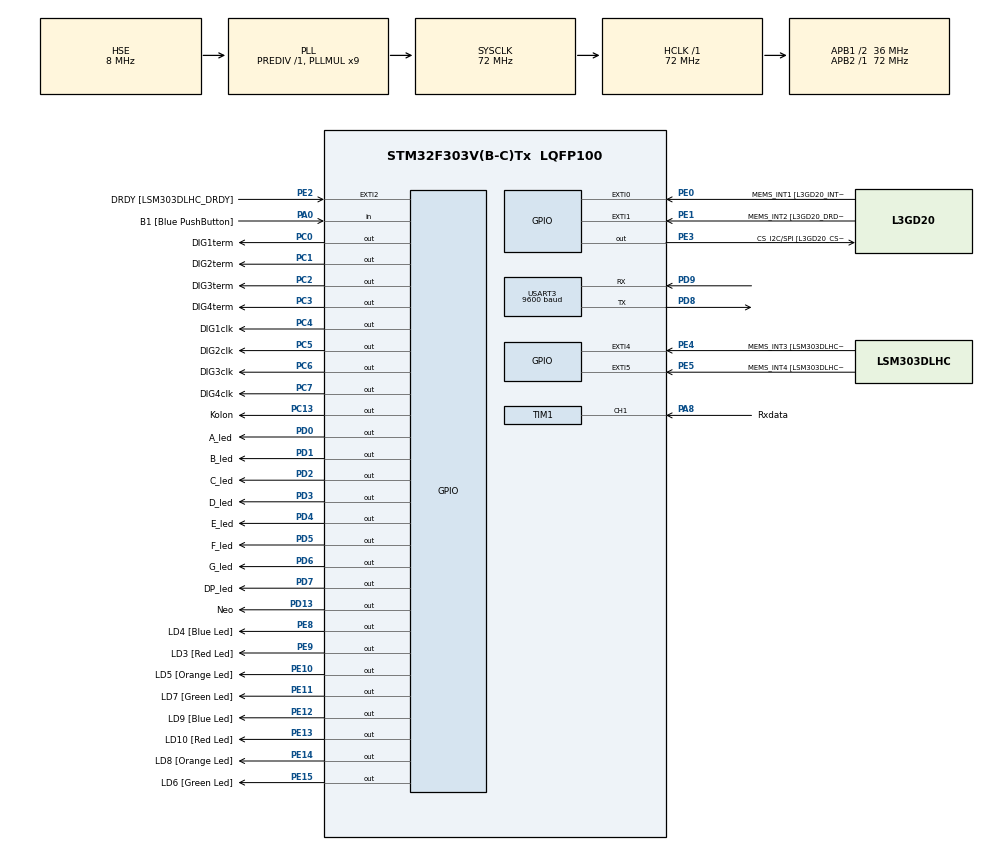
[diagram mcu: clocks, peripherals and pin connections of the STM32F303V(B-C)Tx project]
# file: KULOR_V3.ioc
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CRC.CRCLength=CRC_POLYLENGTH_8B
CRC.DefaultInitValueUse=DEFAULT_INIT_VALUE_DISABLE
CRC.DefaultPolynomialUse=DEFAULT_POLYNOMIAL_DISABLE
CRC.GeneratingPolynomial=X5+X4+X0
CRC.InputDataFormat=CRC_INPUTDATA_FORMAT_WORDS
FREERTOS.Tasks01=defaultTask,0,128,StartDefaultTask,Default,NULL
Mcu.Family=STM32F3
Mcu.Name=STM32F303V(B-C)Tx
Mcu.Package=LQFP100
NVIC.PriorityGroup=NVIC_PRIORITYGROUP_4
NVIC.TIM1_CC_IRQn=true\:5\:0\:false\:false\:true\:true
NVIC.TIM2_IRQn=true\:0\:0\:false\:false\:true\:false
NVIC.TimeBase=TIM2_IRQn
NVIC.TimeBaseIP=TIM2
PA0.GPIO_Label=B1 [Blue PushButton]
PA0.GPIO_Mode=GPIO_MODE_INPUT
PA0.GPIO_PuPd=GPIO_NOPULL
PA0.Signal=GPIO_Input
PA11.GPIO_Label=DM
PA11.Signal=USB_DM
PA12.GPIO_Label=DP
PA12.Signal=USB_DP
PA13.GPIO_Label=SWDIO
PA13.Signal=SYS_JTMS-SWDIO
PA14.GPIO_Label=SWCLK
PA14.Signal=SYS_JTCK-SWCLK
PA5.GPIO_Label=SPI1_SCK [L3GD20_SCL/SPC]
PA5.GPIO_Mode=GPIO_MODE_AF_PP
PA5.GPIO_PuPd=GPIO_NOPULL
PA5.GPIO_Speed=GPIO_SPEED_FREQ_LOW
PA5.Signal=SPI1_SCK
PA6.GPIO_Label=SPI1_MISO [L3GD20_SA0/SDO]
PA6.GPIO_Mode=GPIO_MODE_AF_PP
PA6.GPIO_PuPd=GPIO_NOPULL
PA6.GPIO_Speed=GPIO_SPEED_FREQ_LOW
PA6.Signal=SPI1_MISO
PA7.GPIO_Label=SPI1_MISO [L3GD20_SDA/SDI/SDO]
PA7.GPIO_Mode=GPIO_MODE_AF_PP
PA7.GPIO_PuPd=GPIO_NOPULL
PA7.GPIO_Speed=GPIO_SPEED_FREQ_LOW
PA7.Signal=SPI1_MOSI
PA8.GPIO_Label=Rxdata
PA8.Signal=S_TIM1_CH1
PB3.GPIO_Label=SWO
PB3.Signal=SYS_JTDO-TRACESWO
PB6.GPIO_FM6=__NULL
PB6.GPIO_Label=I2C1_SCL [LSM303DLHC_SCL]
PB6.GPIO_Mode=GPIO_MODE_AF_OD
PB6.GPIO_PuPd=GPIO_NOPULL
PB6.GPIO_Speed=GPIO_SPEED_FREQ_LOW
PB6.Signal=I2C1_SCL
PB7.GPIO_FM7=__NULL
PB7.GPIO_Label=I2C1_SDA [LSM303DLHC_SDA]
PB7.GPIO_Mode=GPIO_MODE_AF_OD
PB7.GPIO_PuPd=GPIO_NOPULL
PB7.GPIO_Speed=GPIO_SPEED_FREQ_LOW
PB7.Signal=I2C1_SDA
PC0.GPIO_Label=DIG1term
PC0.Signal=GPIO_Output
PC1.GPIO_Label=DIG2term
PC1.Signal=GPIO_Output
PC13.GPIO_Label=Kolon
PC13.Signal=GPIO_Output
PC14-OSC32_IN.GPIO_Label=OSC32_IN
PC14-OSC32_IN.Signal=RCC_OSC32_IN
PC15-OSC32_OUT.GPIO_Label=OSC32_OUT
PC15-OSC32_OUT.Signal=RCC_OSC32_OUT
PC2.GPIO_Label=DIG3term
PC2.Signal=GPIO_Output
PC3.GPIO_Label=DIG4term
PC3.Signal=GPIO_Output
PC4.GPIO_Label=DIG1clk
PC4.Signal=GPIO_Output
PC5.GPIO_Label=DIG2clk
PC5.Signal=GPIO_Output
PC6.GPIO_Label=DIG3clk
PC6.Signal=GPIO_Output
PC7.GPIO_Label=DIG4clk
PC7.Signal=GPIO_Output
PD0.GPIO_Label=A_led
PD0.Signal=GPIO_Output
PD1.GPIO_Label=B_led
PD1.Signal=GPIO_Output
PD13.GPIO_Label=Neo
PD13.Signal=GPIO_Output
PD2.GPIO_Label=C_led
PD2.Signal=GPIO_Output
PD3.GPIO_Label=D_led
PD3.Signal=GPIO_Output
PD4.GPIO_Label=E_led
PD4.Signal=GPIO_Output
PD5.GPIO_Label=F_led
PD5.Signal=GPIO_Output
PD6.GPIO_Label=G_led
PD6.Signal=GPIO_Output
PD7.GPIO_Label=DP_led
PD7.Signal=GPIO_Output
PD8.Mode=Asynchronous
PD8.Signal=USART3_TX
PD9.Mode=Asynchronous
PD9.Signal=USART3_RX
PE0.GPIO_Label=MEMS_INT1 [L3GD20_INT1]
PE0.GPIO_ModeDefaultEXTI=GPIO_MODE_EVT_RISING
PE0.GPIO_PuPd=GPIO_NOPULL
PE0.Signal=GPXTI0
PE1.GPIO_Label=MEMS_INT2 [L3GD20_DRDY/INT2]
PE1.GPIO_ModeDefaultEXTI=GPIO_MODE_EVT_RISING
PE1.GPIO_PuPd=GPIO_NOPULL
PE1.Signal=GPXTI1
PE10.GPIO_Label=LD5 [Orange Led]
PE10.GPIO_ModeDefaultOutputPP=GPIO_MODE_OUTPUT_PP
PE10.GPIO_PuPd=GPIO_NOPULL
PE10.GPIO_Speed=GPIO_SPEED_FREQ_LOW
PE10.Signal=GPIO_Output
PE11.GPIO_Label=LD7 [Green Led]
PE11.GPIO_ModeDefaultOutputPP=GPIO_MODE_OUTPUT_PP
PE11.GPIO_PuPd=GPIO_NOPULL
PE11.GPIO_Speed=GPIO_SPEED_FREQ_LOW
PE11.Signal=GPIO_Output
PE12.GPIO_Label=LD9 [Blue Led]
PE12.GPIO_ModeDefaultOutputPP=GPIO_MODE_OUTPUT_PP
PE12.GPIO_PuPd=GPIO_NOPULL
PE12.GPIO_Speed=GPIO_SPEED_FREQ_LOW
PE12.Signal=GPIO_Output
PE13.GPIO_Label=LD10 [Red Led]
PE13.GPIO_ModeDefaultOutputPP=GPIO_MODE_OUTPUT_PP
PE13.GPIO_PuPd=GPIO_NOPULL
PE13.GPIO_Speed=GPIO_SPEED_FREQ_LOW
PE13.Signal=GPIO_Output
PE14.GPIO_Label=LD8 [Orange Led]
PE14.GPIO_ModeDefaultOutputPP=GPIO_MODE_OUTPUT_PP
PE14.GPIO_PuPd=GPIO_NOPULL
PE14.GPIO_Speed=GPIO_SPEED_FREQ_LOW
PE14.Signal=GPIO_Output
PE15.GPIO_Label=LD6 [Green Led]
PE15.GPIO_ModeDefaultOutputPP=GPIO_MODE_OUTPUT_PP
PE15.GPIO_PuPd=GPIO_NOPULL
PE15.GPIO_Speed=GPIO_SPEED_FREQ_LOW
PE15.Signal=GPIO_Output
PE2.GPIO_Label=DRDY [LSM303DLHC_DRDY]
PE2.GPIO_ModeDefaultEXTI=GPIO_MODE_EVT_RISING
PE2.GPIO_PuPd=GPIO_NOPULL
PE2.Signal=GPXTI2
PE3.GPIO_Label=CS_I2C/SPI [L3GD20_CS_I2C/SPI]
PE3.GPIO_ModeDefaultOutputPP=GPIO_MODE_OUTPUT_PP
PE3.GPIO_PuPd=GPIO_NOPULL
PE3.GPIO_Speed=GPIO_SPEED_FREQ_LOW
PE3.Signal=GPIO_Output
PE4.GPIO_Label=MEMS_INT3 [LSM303DLHC_INT1]
PE4.GPIO_ModeDefaultEXTI=GPIO_MODE_EVT_RISING
PE4.GPIO_PuPd=GPIO_NOPULL
PE4.Signal=GPXTI4
PE5.GPIO_Label=MEMS_INT4 [LSM303DLHC_INT2]
PE5.GPIO_ModeDefaultEXTI=GPIO_MODE_EVT_RISING
PE5.GPIO_PuPd=GPIO_NOPULL
PE5.Signal=GPXTI5
PE8.GPIO_Label=LD4 [Blue Led]
PE8.GPIO_ModeDefaultOutputPP=GPIO_MODE_OUTPUT_PP
PE8.GPIO_PuPd=GPIO_NOPULL
PE8.GPIO_Speed=GPIO_SPEED_FREQ_LOW
PE8.Signal=GPIO_Output
PE9.GPIO_Label=LD3 [Red Led]
PE9.GPIO_ModeDefaultOutputPP=GPIO_MODE_OUTPUT_PP
PE9.GPIO_PuPd=GPIO_NOPULL
PE9.GPIO_Speed=GPIO_SPEED_FREQ_LOW
PE9.Signal=GPIO_Output
PF0-OSC_IN.GPIO_Label=OSC_IN
PF0-OSC_IN.Mode=HSE-External-Oscillator
PF0-OSC_IN.Signal=RCC_OSC_IN
PF1-OSC_OUT.GPIO_Label=OSC_OUT
PF1-OSC_OUT.Mode=HSE-External-Oscillator
PF1-OSC_OUT.Signal=RCC_OSC_OUT
ProjectManager.HeapSize=0x200
ProjectManager.StackSize=0x400
ProjectManager.TargetToolchain=EWARM
RCC.AHBFreq_Value=72000000
RCC.APB1CLKDivider=RCC_HCLK_DIV2
RCC.APB1Freq_Value=36000000
RCC.APB1TimFreq_Value=72000000
RCC.APB2Freq_Value=72000000
RCC.APB2TimFreq_Value=72000000
RCC.CortexFreq_Value=72000000
RCC.HCLKFreq_Value=72000000
RCC.HSE_VALUE=8000000
RCC.HSIState=RCC_HSI_ON
RCC.HSI_VALUE=8000000
RCC.LSE_VALUE=32768
RCC.PLLMUL=RCC_PLL_MUL9
RCC.PLLSourceVirtual=RCC_PLLSOURCE_HSE
RCC.SYSCLKFreq_VALUE=72000000
RCC.SYSCLKSourceVirtual=RCC_SYSCLKSOURCE_PLLCLK
RCC.USBFreq_Value=72000000
SH.S_TIM1_CH1.0=TIM1_CH1,TriggerSource_TI1FP1
SH.S_TIM1_CH1.1=TIM1_CH1,Input_Capture1_from_TI1
SH.S_TIM1_CH1.2=TIM1_CH1,Input_Capture2_from_TI1
TIM1.Channel-Input_Capture2_from_TI1=TIM_CHANNEL_2
TIM1.ICPolarity_CH2=TIM_INPUTCHANNELPOLARITY_FALLING
TIM1.Period=0xFFFF
TIM1.Prescaler=71
USART3.BaudRate=9600
VP_CRC_VS_CRC.Mode=CRC_Activate
VP_FREERTOS_VS_ENABLE.Mode=Enabled
VP_RTC_VS_RTC_Activate.Mode=RTC_Enabled
VP_RTC_VS_RTC_Calendar.Mode=RTC_Calendar
VP_SYS_VS_tim2.Mode=TIM2
VP_TIM1_VS_ClockSourceINT.Mode=Internal
VP_TIM1_VS_ControllerModeReset.Mode=Reset Mode
board=STM32F3DISCOVERY

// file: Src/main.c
/**
  ******************************************************************************
  * File Name          : main.c
  * Description        : Main program body
  ******************************************************************************
  *
  * Copyright (c) 2017 STMicroelectronics International N.V.
  * All rights reserved.
  *
  * Redistribution and use in source and binary forms, with or without
  * modification, are permitted, provided that the following conditions are met:

  ******************************************************************************
  */
#include "main.h"
#include "stm32f3xx_hal.h"
#include "cmsis_os.h"
#include "crc.h"
#include "rtc.h"
#include "tim.h"
#include "usart.h"
#include "gpio.h"
#include "stm32f3_discovery.h"
#include "Kulor_Funktioner.h"

/* USER CODE BEGIN PV */
/* Private variables ---------------------------------------------------------*/

/* USER CODE END PV */

void SystemClock_Config(void);
void Error_Handler(void);
void MX_FREERTOS_Init(void);

/* USER CODE BEGIN PFP */
/* Private function prototypes -----------------------------------------------*/

/* USER CODE END PFP */

int main(void)
{

  /* MCU Configuration----------------------------------------------------------*/

  /* Reset of all peripherals, Initializes the Flash interface and the Systick. */
  HAL_Init();

  /* Configure the system clock */
  SystemClock_Config();

  /* Initialize all configured peripherals */
  MX_GPIO_Init();
  MX_CRC_Init();
  MX_RTC_Init();
  MX_TIM1_Init();
  MX_USART3_UART_Init();
  RTC_CLOCK_SETINGS();
  /* USER CODE BEGIN 2 */
   set_clock_serial();
  /* USER CODE END 2 */

  /* Call init function for freertos objects (in freertos.c) */
  MX_FREERTOS_Init();

  /* Start scheduler */
  osKernelStart();

  /* We should never get here as control is now taken by the scheduler */

  /* Infinite loop */
  while (1)
  {

  }

}

/** System Clock Configuration
*/
void SystemClock_Config(void)
{

  RCC_OscInitTypeDef RCC_OscInitStruct;
  RCC_ClkInitTypeDef RCC_ClkInitStruct;
  RCC_PeriphCLKInitTypeDef PeriphClkInit;

    /**Initializes the CPU, AHB and APB busses clocks
    */
  RCC_OscInitStruct.OscillatorType = RCC_OSCILLATORTYPE_LSI|RCC_OSCILLATORTYPE_HSE;
  RCC_OscInitStruct.HSEState = RCC_HSE_ON;
  RCC_OscInitStruct.HSEPredivValue = RCC_HSE_PREDIV_DIV1;
  RCC_OscInitStruct.HSIState = RCC_HSI_ON;
  RCC_OscInitStruct.LSIState = RCC_LSI_ON;
  RCC_OscInitStruct.PLL.PLLState = RCC_PLL_ON;
  RCC_OscInitStruct.PLL.PLLSource = RCC_PLLSOURCE_HSE;
  RCC_OscInitStruct.PLL.PLLMUL = RCC_PLL_MUL9;
  if (HAL_RCC_OscConfig(&RCC_OscInitStruct) != HAL_OK)
  {
    Error_Handler();
  }

    /**Initializes the CPU, AHB and APB busses clocks
    */
  RCC_ClkInitStruct.ClockType = RCC_CLOCKTYPE_HCLK|RCC_CLOCKTYPE_SYSCLK
                              |RCC_CLOCKTYPE_PCLK1|RCC_CLOCKTYPE_PCLK2;
  RCC_ClkInitStruct.SYSCLKSource = RCC_SYSCLKSOURCE_PLLCLK;
  RCC_ClkInitStruct.AHBCLKDivider = RCC_SYSCLK_DIV1;
  RCC_ClkInitStruct.APB1CLKDivider = RCC_HCLK_DIV2;
  RCC_ClkInitStruct.APB2CLKDivider = RCC_HCLK_DIV1;

  if (HAL_RCC_ClockConfig(&RCC_ClkInitStruct, FLASH_LATENCY_2) != HAL_OK)
  {
    Error_Handler();
  }

  PeriphClkInit.PeriphClockSelection = RCC_PERIPHCLK_USART3|RCC_PERIPHCLK_RTC
                              |RCC_PERIPHCLK_TIM1;
  PeriphClkInit.Usart3ClockSelection = RCC_USART3CLKSOURCE_PCLK1;
  PeriphClkInit.RTCClockSelection = RCC_RTCCLKSOURCE_LSI;
  PeriphClkInit.Tim1ClockSelection = RCC_TIM1CLK_HCLK;
  if (HAL_RCCEx_PeriphCLKConfig(&PeriphClkInit) != HAL_OK)
  {
    Error_Handler();
  }

    /**Configure the Systick interrupt time
    */
  HAL_SYSTICK_Config(HAL_RCC_GetHCLKFreq()/1000);

    /**Configure the Systick
    */
  HAL_SYSTICK_CLKSourceConfig(SYSTICK_CLKSOURCE_HCLK);

  /* SysTick_IRQn interrupt configuration */
  HAL_NVIC_SetPriority(SysTick_IRQn, 15, 0);
}

void HAL_TIM_PeriodElapsedCallback(TIM_HandleTypeDef *htim)
{
  if (htim->Instance == TIM2) {
    HAL_IncTick();
  }
}

void Error_Handler(void)
{
  while(1)
  {
  }
}

/************************ (C) COPYRIGHT STMicroelectronics *****END OF FILE****/

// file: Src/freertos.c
/**
  ******************************************************************************
  * File Name          : freertos.c
  * Description        : Code for freertos applications
  ******************************************************************************
  *
  * Copyright (c) 2017 STMicroelectronics International N.V.
  * All rights reserved.
  *
  * Redistribution and use in source and binary forms, with or without
  * modification, are permitted, provided that the following conditions are met:
  *
  * 1. Redistribution of source code must retain the above copyright notice,
  *    this list of conditions and the following disclaimer.
  * 2. Redistributions in binary form must reproduce the above copyright notice,
  *    this list of conditions and the following disclaimer in the documentation
  *    and/or other materials provided with the distribution.
  * 3. Neither the name of STMicroelectronics nor the names of other
  *    contributors to this software may be used to endorse or promote products
  *    derived from this software without specific written permission.
  * 4. This software, including modifications and/or derivative works of this
  *    software, must execute solely and exclusively on microcontroller or
  *    microprocessor devices manufactured by or for STMicroelectronics.
  * 5. Redistribution and use of this software other than as permitted under
  *    this license is void and will automatically terminate your rights under
  *    this license.
  *
  * THIS SOFTWARE IS PROVIDED BY STMICROELECTRONICS AND CONTRIBUTORS "AS IS"
  * AND ANY EXPRESS, IMPLIED OR STATUTORY WARRANTIES, INCLUDING, BUT NOT
  * LIMITED TO, THE IMPLIED WARRANTIES OF MERCHANTABILITY, FITNESS FOR A
  * PARTICULAR PURPOSE AND NON-INFRINGEMENT OF THIRD PARTY INTELLECTUAL PROPERTY
  * RIGHTS ARE DISCLAIMED TO THE FULLEST EXTENT PERMITTED BY LAW. IN NO EVENT
  * SHALL STMICROELECTRONICS OR CONTRIBUTORS BE LIABLE FOR ANY DIRECT, INDIRECT,
  * INCIDENTAL, SPECIAL, EXEMPLARY, OR CONSEQUENTIAL DAMAGES (INCLUDING, BUT NOT
  * LIMITED TO, PROCUREMENT OF SUBSTITUTE GOODS OR SERVICES; LOSS OF USE, DATA,
  * OR PROFITS; OR BUSINESS INTERRUPTION) HOWEVER CAUSED AND ON ANY THEORY OF
  * LIABILITY, WHETHER IN CONTRACT, STRICT LIABILITY, OR TORT (INCLUDING
  * NEGLIGENCE OR OTHERWISE) ARISING IN ANY WAY OUT OF THE USE OF THIS SOFTWARE,
  * EVEN IF ADVISED OF THE POSSIBILITY OF SUCH DAMAGE.
  *
  ******************************************************************************
  */

#include "FreeRTOS.h"
#include "task.h"
#include "cmsis_os.h"
#include "Kulor_Funktioner.h"
#include "stdbool.h"

osThreadId defaultTaskHandle;

void StartDefaultTask(void const * argument);
void DisplayTask(void const * argument);
//void UartTask(void const * argument);

void MX_FREERTOS_Init(void); /* (MISRA C 2004 rule 8.1) */

/* Hook prototypes */

/* Init FreeRTOS */

void MX_FREERTOS_Init(void) {

  /* Create the thread(s) */
  /* definition and creation of defaultTask */
  osThreadDef(defaultTask, StartDefaultTask, osPriorityNormal, 0, 128);
  defaultTaskHandle = osThreadCreate(osThread(defaultTask), NULL);

  /* USER CODE BEGIN RTOS_THREADS */
  osThreadDef(Diplay_Task, DisplayTask, osPriorityNormal, 0, 128);
  osThreadCreate(osThread(Diplay_Task), NULL);

  /*osThreadDef(Uart_task,UartTask,osPriorityNormal,0,128);
  osThreadCreate(osThread(Uart_task),NULL);*/

  /* add threads, ... */
  /* USER CODE END RTOS_THREADS */

}

/* StartDefaultTask function */
void StartDefaultTask(void const * argument)
{

  for(;;){
    osDelay(1);
  }
}

/* USER CODE BEGIN Application */
void DisplayTask(void const * argument){
  int i=0;
   while(true){
     UppDateDisplay(i);
     vTaskDelay(1);
     i++;

     if(i==9)
       i=0;

}

}

/*void UartTask(void const * argument){
  //set_clock_serial();

}*/
/* USER CODE END Application */

/************************ (C) COPYRIGHT STMicroelectronics *****END OF FILE****/
